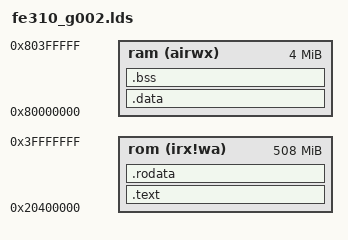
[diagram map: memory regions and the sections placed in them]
OUTPUT_ARCH( "riscv" )

ENTRY( _start )

MEMORY
{
    ram (airwx) : ORIGIN = 0x80000000, LENGTH = 0x400000
    rom (irx!wa) : ORIGIN = 0x20400000, LENGTH = 0x1fc00000
}

PHDRS
{
  text PT_LOAD;
  data PT_LOAD;
  bss PT_LOAD;
}

SECTIONS
{
  .text : {
    PROVIDE(_text_start = .);
    *(.text.init) *(.text .text.*)
    PROVIDE(_text_end = .);
  } >rom :text

  .rodata : {
    PROVIDE(_rodata_start = .);
    *(.rodata .rodata.*)
    PROVIDE(_rodata_end = .);
  } >rom :text

  .data : {
    . = ALIGN(4096);
    PROVIDE(_data_start = .);
    *(.sdata .sdata.*) *(.data .data.*)
    PROVIDE(_data_end = .);
  } >ram :data

  .bss :{
    PROVIDE(_bss_start = .);
    *(.sbss .sbss.*) *(.bss .bss.*)
    PROVIDE(_bss_end = .);
  } >ram :bss

  PROVIDE(_memory_start = ORIGIN(ram));
  PROVIDE(_memory_end = ORIGIN(ram) + LENGTH(ram));
}
